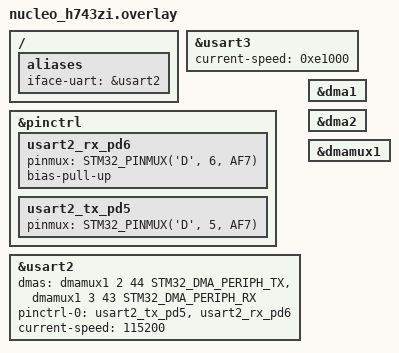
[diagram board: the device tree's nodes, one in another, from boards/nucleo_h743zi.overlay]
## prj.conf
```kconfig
# Iface library
CONFIG_CK_IFACE_LIB_UART=y
CONFIG_CK_IFACE_NUM_PACKET_BUFFERS=40
CONFIG_CK_IFACE_UART_STACK_HEAP_SIZE=5000
CONFIG_CK_IFACE_RECV_RING_BUFER_SIZE=5000
# CONFIG_CK_IFACE_NUM_UART_SOCKETS=2
CONFIG_CK_IFACE_LIB_ASSEMBLER_DEBUG_LEVEL=3
# CONFIG_CK_IFACE_RECV_CB_BUFFER_SIZE=128
CONFIG_CK_IFACE_UART_STACK_THREAD_STACK_SIZE=10000
CONFIG_CK_IFACE_UART_STACK_THREAD_PRIORITY=7

# Logging
CONFIG_LOG=y
# CONFIG_LOG_MODE_IMMEDIATE=y
CONFIG_LOG_MODE_DEFERRED=y
CONFIG_LOG_BACKEND_SHOW_COLOR=y

# System
CONFIG_NEWLIB_LIBC=y
CONFIG_MAIN_STACK_SIZE=10000

# Networking config
# CONFIG_NETWORKING=y
# CONFIG_NET_CONFIG_AUTO_INIT=y
# CONFIG_NET_CONFIG_SETTINGS=y
# CONFIG_NET_IPV4=y
# CONFIG_NET_DHCPV4=y
# CONFIG_NET_CONFIG_NEED_IPV4=y
# CONFIG_DNS_RESOLVER=y

# Thread-Aware debugging
CONFIG_THREAD_MONITOR=y
CONFIG_INIT_STACKS=y
CONFIG_DEBUG_THREAD_INFO=y
CONFIG_THREAD_STACK_INFO=y
CONFIG_THREAD_NAME=y

# Disable code for debuggin
CONFIG_DEBUG_OPTIMIZATIONS=y
CONFIG_EXCEPTION_STACK_TRACE=y
CONFIG_DEBUG_INFO=y
CONFIG_PINCTRL=y
```

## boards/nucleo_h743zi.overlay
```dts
&usart3 {
    current-speed = <0xe1000>;
};

&pinctrl {
    usart2_rx_pd6: usart2_rx_pd6 {
        pinmux = <STM32_PINMUX('D', 6, AF7)>;
        bias-pull-up;
    };

    usart2_tx_pd5: usart2_tx_pd5 {
        pinmux = <STM32_PINMUX('D', 5, AF7)>;
    };
};

&usart2 {
    dmas = <&dmamux1 2 44 STM32_DMA_PERIPH_TX>,
		   <&dmamux1 3 43 STM32_DMA_PERIPH_RX>;
    dma-names = "tx", "rx";
    status = "okay";
    pinctrl-0 = <&usart2_tx_pd5 &usart2_rx_pd6>;
    pinctrl-names = "default";
    current-speed = <115200>;
};

&dma1 {
	status = "okay";
};

&dma2 {
	status = "okay";
};

&dmamux1 {
	status = "okay";
};

/ {
    aliases {
        iface-uart = &usart2;
    };
};
```

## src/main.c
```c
// Standard includes
#include <errno.h>
#include <stdio.h>
#include <string.h>

// Zephyr includes
#include <zephyr/device.h>
#include <zephyr/kernel.h>
#include <zephyr/logging/log.h>

// Corekinect includes
#include <corekinect/iface/iface.h>  // <- This is how you'd include the library in your app

LOG_MODULE_REGISTER(socket_server);

// Uart Device
#define UART_NODE DT_ALIAS(iface_uart)  // This has to match the entry in the .overaly file
const struct device *const uart_dev = DEVICE_DT_GET(UART_NODE);

int main(void) {
    // Server config
    iface_t server_cfg =
        {
            .type = IFACE_TYPE_UART,
            .link = IFACE_LINK_TYPE_SERVER,
            .p_uart_dev = uart_dev,
        };

    while (true) {
        if (!iface_create(&server_cfg)) {
            LOG_ERR("Could not create iface");
            break;
        }

        LOG_INF("Server is running and waiting for connection...");

        bool timeout = false;
        if (!iface_accept(&server_cfg, &timeout)) {
            LOG_ERR("Error accepting connection, timeout: %s", timeout ? "yes" : "no");
            break;
        }

        LOG_INF("Server got a connection from client");

        bool conn_closed = false;
        while (true) {
            uint16_t recv_bytes = 0;
            static char buffer[1024] = {0};
            if (!iface_recv(&server_cfg, buffer, sizeof(buffer), &recv_bytes, &conn_closed, &timeout)) {
                LOG_ERR("Could not recv, timeout: %s, conn_closed: %s", timeout ? "yes" : "no", conn_closed ? "yes" : "no");
                break;
            }

            LOG_INF("Server received: %s", buffer);
            uint16_t sent_bytes = 0;
            if (!iface_send(&server_cfg, buffer, recv_bytes, &sent_bytes, &conn_closed, &timeout)) {
                LOG_ERR("Could not send, timeout: %s, conn_closed: %s", timeout ? "yes" : "no", conn_closed ? "yes" : "no");
                break;
            }
        }

        if (!iface_close(&server_cfg)) {
            LOG_ERR("Could not close iface");
            break;
        }
    }

    LOG_ERR("Fatal error occurred in %s", __func__);
    k_fatal_halt(0);
}
```
